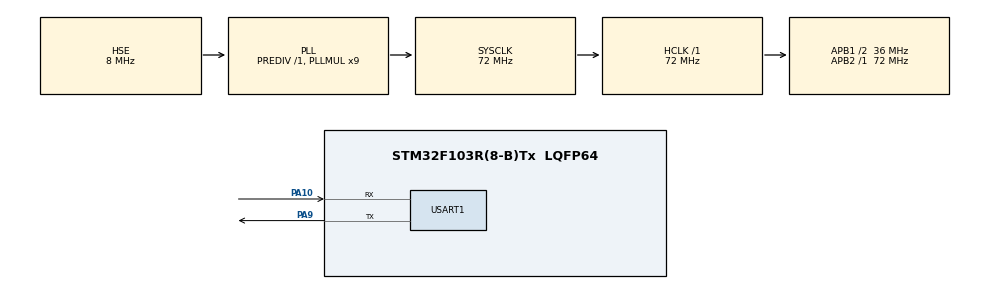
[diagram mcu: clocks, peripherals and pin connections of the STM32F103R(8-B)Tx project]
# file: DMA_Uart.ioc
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Dma.Request0=USART1_TX
Dma.USART1_TX.0.Direction=DMA_MEMORY_TO_PERIPH
Dma.USART1_TX.0.Instance=DMA1_Channel4
Dma.USART1_TX.0.MemDataAlignment=DMA_MDATAALIGN_BYTE
Dma.USART1_TX.0.MemInc=DMA_MINC_ENABLE
Dma.USART1_TX.0.Mode=DMA_NORMAL
Dma.USART1_TX.0.PeriphDataAlignment=DMA_PDATAALIGN_BYTE
Dma.USART1_TX.0.PeriphInc=DMA_PINC_DISABLE
Dma.USART1_TX.0.Priority=DMA_PRIORITY_LOW
Mcu.Family=STM32F1
Mcu.Name=STM32F103R(8-B)Tx
Mcu.Package=LQFP64
NVIC.DMA1_Channel4_IRQn=true\:0\:0\:false\:false\:true\:false\:true
NVIC.PriorityGroup=NVIC_PRIORITYGROUP_4
NVIC.TIM1_UP_IRQn=true\:0\:0\:false\:false\:true\:true\:true
NVIC.USART1_IRQn=true\:0\:0\:false\:false\:true\:true\:true
PA10.Mode=Asynchronous
PA10.Signal=USART1_RX
PA9.Mode=Asynchronous
PA9.Signal=USART1_TX
PD0-OSC_IN.Mode=HSE-External-Oscillator
PD0-OSC_IN.Signal=RCC_OSC_IN
PD1-OSC_OUT.Mode=HSE-External-Oscillator
PD1-OSC_OUT.Signal=RCC_OSC_OUT
ProjectManager.HeapSize=0x200
ProjectManager.StackSize=0x400
ProjectManager.TargetToolchain=MDK-ARM V5.27
RCC.AHBFreq_Value=72000000
RCC.APB1CLKDivider=RCC_HCLK_DIV2
RCC.APB1Freq_Value=36000000
RCC.APB1TimFreq_Value=72000000
RCC.APB2Freq_Value=72000000
RCC.APB2TimFreq_Value=72000000
RCC.HCLKFreq_Value=72000000
RCC.PLLMUL=RCC_PLL_MUL9
RCC.PLLSourceVirtual=RCC_PLLSOURCE_HSE
RCC.SYSCLKFreq_VALUE=72000000
RCC.SYSCLKSource=RCC_SYSCLKSOURCE_PLLCLK
RCC.USBFreq_Value=72000000
TIM1.AutoReloadPreload=TIM_AUTORELOAD_PRELOAD_ENABLE
TIM1.Channel-Output\ Compare1\ No\ Output=TIM_CHANNEL_1
TIM1.Period=1
TIM1.Prescaler=72-1
USART1.VirtualMode=VM_ASYNC
VP_SYS_VS_ND.Mode=No_Debug
VP_TIM1_VS_ClockSourceINT.Mode=Internal
VP_TIM1_VS_no_output1.Mode=Output Compare1 No Output
board=custom

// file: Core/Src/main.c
/* USER CODE BEGIN Header */
/**
  ******************************************************************************
  * @file           : main.c
  * @brief          : Main program body
  ******************************************************************************
  * @attention
  *
  * <h2><center>&copy; Copyright (c) 2021 STMicroelectronics.
  * All rights reserved.</center></h2>
  *
  * This software component is licensed by ST under BSD 3-Clause license,
  * the "License"; You may not use this file except in compliance with the
  * License. You may obtain a copy of the License at:
  *                        opensource.org/licenses/BSD-3-Clause
  *
  ******************************************************************************
  */
  //待研究！！！暂时没有成功
/* USER CODE END Header */
#include "main.h"
#include "dma.h"
#include "tim.h"
#include "usart.h"
#include "gpio.h"

/* USER CODE BEGIN PD */
/**
  * @brief  串口发送函数
  * @retval None
  */
//#include "stdio.h"
//#include "stdarg.h"
//#include "string.h"

//#define    TXBUF_SIZE_MAX    100

//void uartx_printf(UART_HandleTypeDef huartx, const char *format, ...)
//{
//    va_list args;
//    uint32_t length;
//    uint8_t txbuf[TXBUF_SIZE_MAX] = {0};
//
//    va_start(args, format);
//    length = vsnprintf((char *)txbuf, sizeof(txbuf), (char *)format, args);
//    va_end(args);
//    HAL_UART_Transmit_DMA(&huartx, (uint8_t *)txbuf, length);
//    Delay_us(8);
//    memset(txbuf, 0, TXBUF_SIZE_MAX);
//};
/* USER CODE END PD */

void SystemClock_Config(void);

int main(void)
{

  /* MCU Configuration--------------------------------------------------------*/

  /* Reset of all peripherals, Initializes the Flash interface and the Systick. */
  HAL_Init();

  /* Configure the system clock */
  SystemClock_Config();

  /* Initialize all configured peripherals */
  MX_GPIO_Init();
  MX_DMA_Init();
  MX_USART1_UART_Init();
  MX_TIM1_Init();
  /* USER CODE BEGIN 2 */
  uint8_t txbuf[] = "hello_world!\r\n";
  /* USER CODE END 2 */

  /* Infinite loop */
  /* USER CODE BEGIN WHILE */
  while (1)
  {
    HAL_UART_Transmit_DMA(&huart1, (uint8_t *)txbuf, 12);
    Delay_us(5);
    /* USER CODE END WHILE */

  }
}

void SystemClock_Config(void)
{
  RCC_OscInitTypeDef RCC_OscInitStruct = {0};
  RCC_ClkInitTypeDef RCC_ClkInitStruct = {0};

  /** Initializes the RCC Oscillators according to the specified parameters
  * in the RCC_OscInitTypeDef structure.
  */
  RCC_OscInitStruct.OscillatorType = RCC_OSCILLATORTYPE_HSE;
  RCC_OscInitStruct.HSEState = RCC_HSE_ON;
  RCC_OscInitStruct.HSEPredivValue = RCC_HSE_PREDIV_DIV1;
  RCC_OscInitStruct.HSIState = RCC_HSI_ON;
  RCC_OscInitStruct.PLL.PLLState = RCC_PLL_ON;
  RCC_OscInitStruct.PLL.PLLSource = RCC_PLLSOURCE_HSE;
  RCC_OscInitStruct.PLL.PLLMUL = RCC_PLL_MUL9;
  if (HAL_RCC_OscConfig(&RCC_OscInitStruct) != HAL_OK)
  {
    Error_Handler();
  }
  /** Initializes the CPU, AHB and APB buses clocks
  */
  RCC_ClkInitStruct.ClockType = RCC_CLOCKTYPE_HCLK|RCC_CLOCKTYPE_SYSCLK
                              |RCC_CLOCKTYPE_PCLK1|RCC_CLOCKTYPE_PCLK2;
  RCC_ClkInitStruct.SYSCLKSource = RCC_SYSCLKSOURCE_PLLCLK;
  RCC_ClkInitStruct.AHBCLKDivider = RCC_SYSCLK_DIV1;
  RCC_ClkInitStruct.APB1CLKDivider = RCC_HCLK_DIV2;
  RCC_ClkInitStruct.APB2CLKDivider = RCC_HCLK_DIV1;

  if (HAL_RCC_ClockConfig(&RCC_ClkInitStruct, FLASH_LATENCY_2) != HAL_OK)
  {
    Error_Handler();
  }
}

/* USER CODE BEGIN 4 */
void Delay_us(unsigned char cnt)
{
   uint8_t us = 10;
   while(us--)
     while(us--);
}
/* USER CODE END 4 */

void Error_Handler(void)
{
}

/************************ (C) COPYRIGHT STMicroelectronics *****END OF FILE****/
